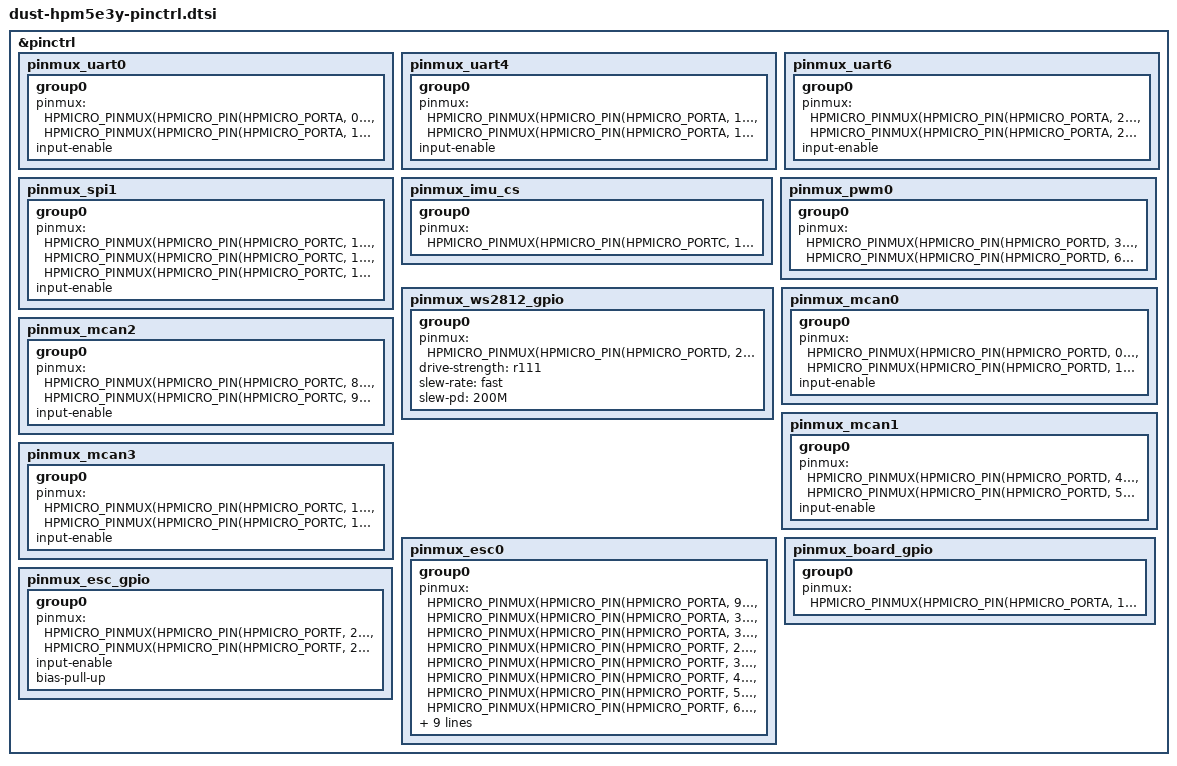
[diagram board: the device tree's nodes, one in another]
/* SPDX-License-Identifier: Apache-2.0 */
#include <dt-bindings/pinctrl/hpmicro-pinctrl-common.h>

&pinctrl {
	pinmux_uart0: pinmux_uart0 {
		group0 { pinmux = <HPMICRO_PINMUX(HPMICRO_PIN(HPMICRO_PORTA, 0), IOC_TYPE_IOC, 0, 2)>, <HPMICRO_PINMUX(HPMICRO_PIN(HPMICRO_PORTA, 1), IOC_TYPE_IOC, 0, 2)>; input-enable; };
	};
	pinmux_uart4: pinmux_uart4 {
		group0 { pinmux = <HPMICRO_PINMUX(HPMICRO_PIN(HPMICRO_PORTA, 16), IOC_TYPE_IOC, 0, 2)>, <HPMICRO_PINMUX(HPMICRO_PIN(HPMICRO_PORTA, 17), IOC_TYPE_IOC, 0, 2)>; input-enable; };
	};
	pinmux_uart6: pinmux_uart6 {
		group0 { pinmux = <HPMICRO_PINMUX(HPMICRO_PIN(HPMICRO_PORTA, 24), IOC_TYPE_IOC, 0, 2)>, <HPMICRO_PINMUX(HPMICRO_PIN(HPMICRO_PORTA, 25), IOC_TYPE_IOC, 0, 2)>; input-enable; };
	};
	pinmux_spi1: pinmux_spi1 {
		group0 { pinmux = <HPMICRO_PINMUX(HPMICRO_PIN(HPMICRO_PORTC, 10), IOC_TYPE_IOC, 0, 5)>, <HPMICRO_PINMUX(HPMICRO_PIN(HPMICRO_PORTC, 12), IOC_TYPE_IOC, 0, 5)>, <HPMICRO_PINMUX(HPMICRO_PIN(HPMICRO_PORTC, 13), IOC_TYPE_IOC, 0, 5)>; input-enable; };
	};
	pinmux_imu_cs: pinmux_imu_cs {
		group0 { pinmux = <HPMICRO_PINMUX(HPMICRO_PIN(HPMICRO_PORTC, 11), IOC_TYPE_IOC, 0, 0)>; };
	};
	pinmux_pwm0: pinmux_pwm0 {
		group0 {
			/* P3: IMU power, P6: buzzer. */
			pinmux = <HPMICRO_PINMUX(HPMICRO_PIN(HPMICRO_PORTD, 3), IOC_TYPE_IOC, 0, 16)>,
				 <HPMICRO_PINMUX(HPMICRO_PIN(HPMICRO_PORTD, 6), IOC_TYPE_IOC, 0, 16)>;
		};
	};
	pinmux_ws2812_gpio: pinmux_ws2812_gpio {
		group0 {
			/* D15 WS2812B DIN: PWM0_P2 pad used as GPIO for timed output. */
			pinmux = <HPMICRO_PINMUX(HPMICRO_PIN(HPMICRO_PORTD, 2), IOC_TYPE_IOC, 0, 0)>;
			drive-strength = "r111";
			slew-rate = "fast";
			slew-pd = "200M";
		};
	};
	pinmux_mcan0: pinmux_mcan0 { group0 { pinmux = <HPMICRO_PINMUX(HPMICRO_PIN(HPMICRO_PORTD, 0), IOC_TYPE_IOC, 0, 7)>, <HPMICRO_PINMUX(HPMICRO_PIN(HPMICRO_PORTD, 1), IOC_TYPE_IOC, 0, 7)>; input-enable; }; };
	pinmux_mcan1: pinmux_mcan1 { group0 { pinmux = <HPMICRO_PINMUX(HPMICRO_PIN(HPMICRO_PORTD, 4), IOC_TYPE_IOC, 0, 7)>, <HPMICRO_PINMUX(HPMICRO_PIN(HPMICRO_PORTD, 5), IOC_TYPE_IOC, 0, 7)>; input-enable; }; };
	pinmux_mcan2: pinmux_mcan2 { group0 { pinmux = <HPMICRO_PINMUX(HPMICRO_PIN(HPMICRO_PORTC, 8), IOC_TYPE_IOC, 0, 7)>, <HPMICRO_PINMUX(HPMICRO_PIN(HPMICRO_PORTC, 9), IOC_TYPE_IOC, 0, 7)>; input-enable; }; };
	pinmux_mcan3: pinmux_mcan3 { group0 { pinmux = <HPMICRO_PINMUX(HPMICRO_PIN(HPMICRO_PORTC, 14), IOC_TYPE_IOC, 0, 7)>, <HPMICRO_PINMUX(HPMICRO_PIN(HPMICRO_PORTC, 15), IOC_TYPE_IOC, 0, 7)>; input-enable; }; };
	pinmux_esc0: pinmux_esc0 {
		group0 {
			pinmux = <HPMICRO_PINMUX(HPMICRO_PIN(HPMICRO_PORTA, 9), IOC_TYPE_IOC, 0, 11)>,
				 <HPMICRO_PINMUX(HPMICRO_PIN(HPMICRO_PORTA, 30), IOC_TYPE_IOC, 0, 11)>, <HPMICRO_PINMUX(HPMICRO_PIN(HPMICRO_PORTA, 31), IOC_TYPE_IOC, 0, 11)>,
				 <HPMICRO_PINMUX(HPMICRO_PIN(HPMICRO_PORTF, 2), IOC_TYPE_IOC, 0, 11)>, <HPMICRO_PINMUX(HPMICRO_PIN(HPMICRO_PORTF, 3), IOC_TYPE_IOC, 0, 11)>, <HPMICRO_PINMUX(HPMICRO_PIN(HPMICRO_PORTF, 4), IOC_TYPE_IOC, 0, 11)>, <HPMICRO_PINMUX(HPMICRO_PIN(HPMICRO_PORTF, 5), IOC_TYPE_IOC, 0, 11)>, <HPMICRO_PINMUX(HPMICRO_PIN(HPMICRO_PORTF, 6), IOC_TYPE_IOC, 0, 11)>, <HPMICRO_PINMUX(HPMICRO_PIN(HPMICRO_PORTF, 7), IOC_TYPE_IOC, 0, 11)>, <HPMICRO_PINMUX(HPMICRO_PIN(HPMICRO_PORTF, 8), IOC_TYPE_IOC, 0, 11)>, <HPMICRO_PINMUX(HPMICRO_PIN(HPMICRO_PORTF, 9), IOC_TYPE_IOC, 0, 11)>, <HPMICRO_PINMUX(HPMICRO_PIN(HPMICRO_PORTF, 10), IOC_TYPE_IOC, 0, 11)>, <HPMICRO_PINMUX(HPMICRO_PIN(HPMICRO_PORTF, 11), IOC_TYPE_IOC, 0, 11)>, <HPMICRO_PINMUX(HPMICRO_PIN(HPMICRO_PORTF, 12), IOC_TYPE_IOC, 0, 11)>, <HPMICRO_PINMUX(HPMICRO_PIN(HPMICRO_PORTF, 13), IOC_TYPE_IOC, 0, 11)>, <HPMICRO_PINMUX(HPMICRO_PIN(HPMICRO_PORTF, 14), IOC_TYPE_IOC, 0, 11)>;
			input-enable;
		};
	};
	pinmux_board_gpio: pinmux_board_gpio {
		group0 {
			pinmux = <HPMICRO_PINMUX(HPMICRO_PIN(HPMICRO_PORTA, 18), IOC_TYPE_IOC, 0, 0)>;
		};
	};
	pinmux_esc_gpio: pinmux_esc_gpio { group0 { pinmux = <HPMICRO_PINMUX(HPMICRO_PIN(HPMICRO_PORTF, 22), IOC_TYPE_IOC, 0, 0)>, <HPMICRO_PINMUX(HPMICRO_PIN(HPMICRO_PORTF, 23), IOC_TYPE_IOC, 0, 0)>; input-enable; bias-pull-up; }; };
};
